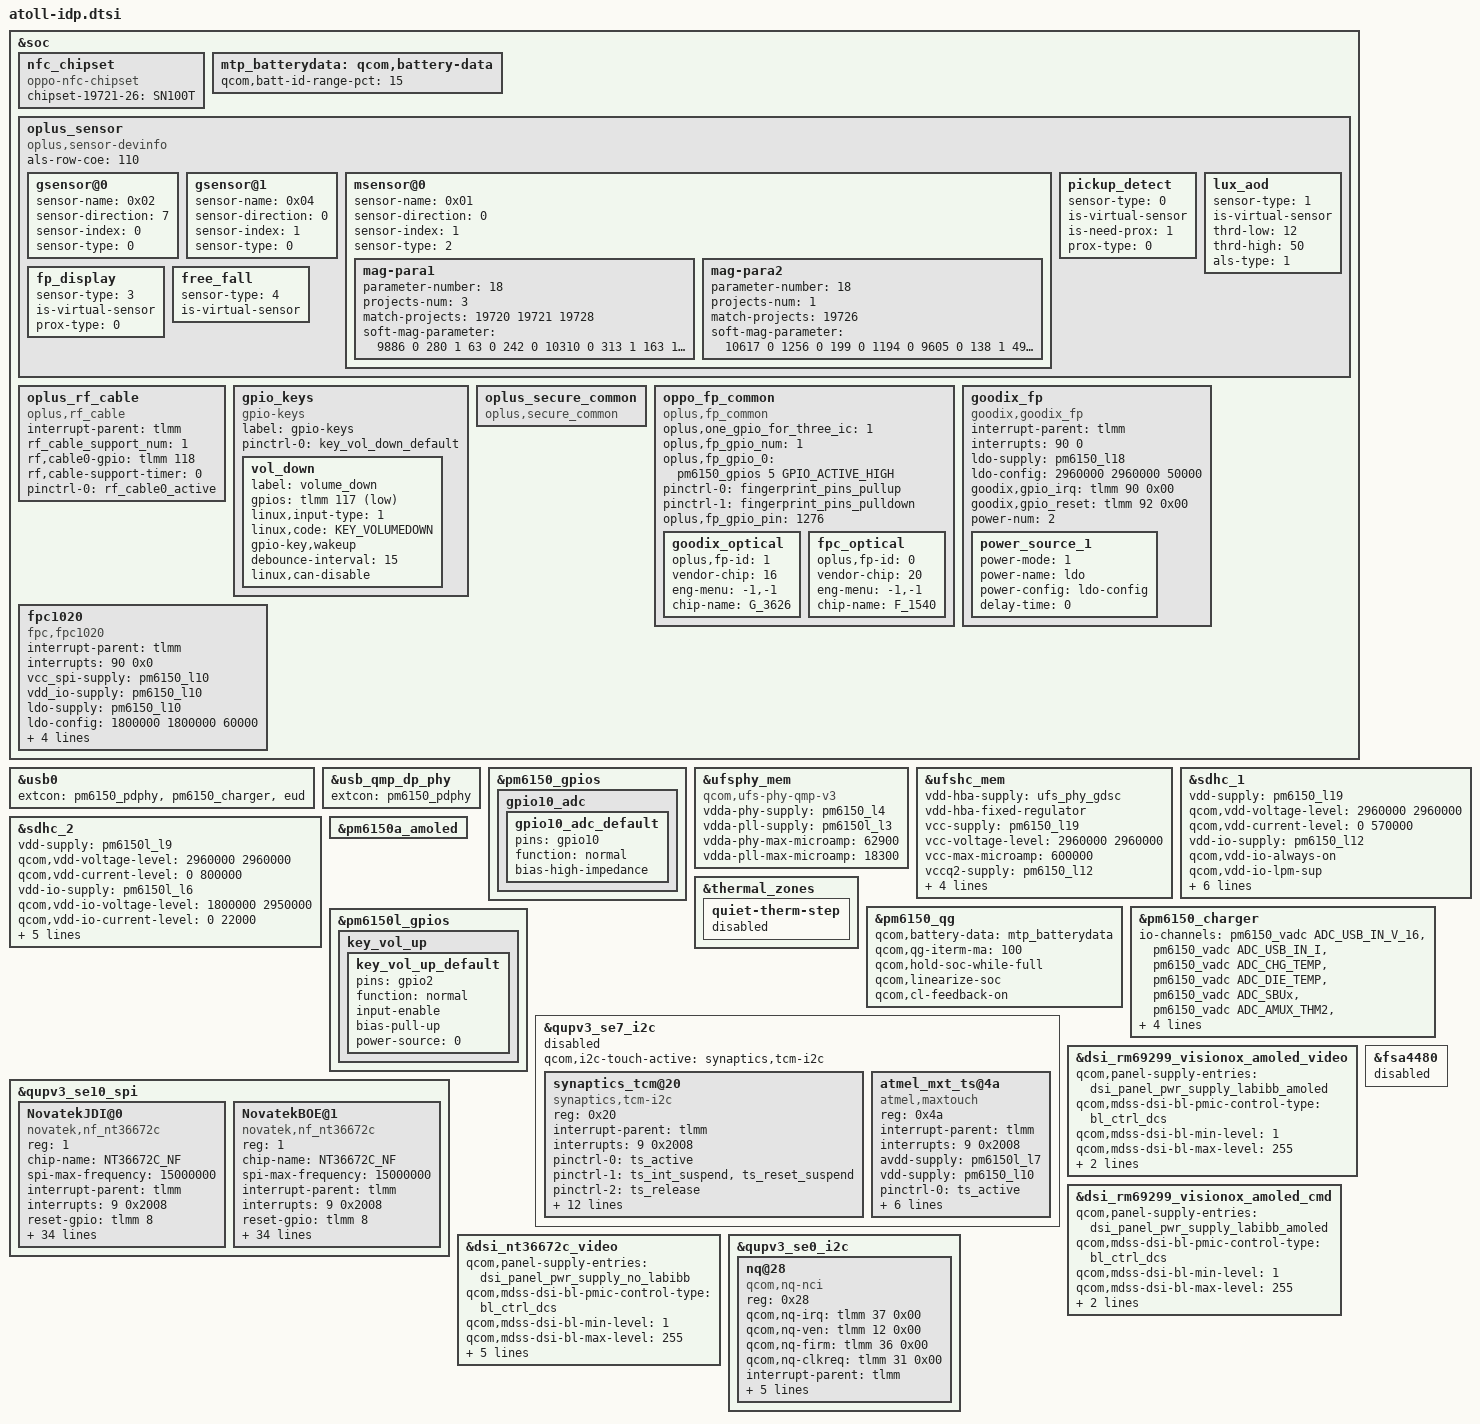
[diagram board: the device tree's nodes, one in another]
/* Copyright (c) 2019-2020, The Linux Foundation. All rights reserved.
 *
 * This program is free software; you can redistribute it and/or modify
 * it under the terms of the GNU General Public License version 2 and
 * only version 2 as published by the Free Software Foundation.
 *
 * This program is distributed in the hope that it will be useful,
 * but WITHOUT ANY WARRANTY; without even the implied warranty of
 * MERCHANTABILITY or FITNESS FOR A PARTICULAR PURPOSE.  See the
 * GNU General Public License for more details.
 */

#include <dt-bindings/gpio/gpio.h>
#include <dt-bindings/pinctrl/qcom,pmic-gpio.h>
#include <dt-bindings/iio/qcom,spmi-vadc.h>
#include <dt-bindings/input/input.h>
#include "atoll-camera-sensor-idp.dtsi"
#include "atoll-sde-display.dtsi"
#include "sdmmagpie-thermal-overlay.dtsi"

&soc {
	//#ifdef VENDOR_EDIT
	nfc_chipset {
		compatible = "oppo-nfc-chipset";
		chipset-19721-26 = "SN100T";
	};
	//#endif /* VENDOR_EDIT */

	mtp_batterydata: qcom,battery-data {
		qcom,batt-id-range-pct = <15>;
		#include "qg-batterydata-alium-3600mah.dtsi"
	};
	//#ifdef VENDOR_EDIT
	/*enum sensor_id { OPPO_ACCEL,OPPO_GYRO,OPPO_MAG,OPPO_LIGHT,OPPO_PROXIMITY,OPPO_SAR,OPPO_CT,OPPO_BAROMETER,SENSORS_NUM};*/
	oplus_sensor {
		compatible = "oplus,sensor-devinfo";
		als-row-coe = <110>;
		/*enum {LSM6DSM = 0x01, BMI160 = 0x02, LSM6DS3 = 0x04};*/
		gsensor@0 {
			sensor-name = <0x02>;//BMI160
			sensor-direction = <7>;
			sensor-index = <0>;//source num
			sensor-type = <0>;//OPPO_ACCEL
		};
		gsensor@1 {
			sensor-name = <0x04>;//LSM6DS3
			sensor-direction = <0>;
			sensor-index = <1>;//source num
			sensor-type = <0>;//OPPO_ACCEL
		};
		/* enum {AKM0991X = 0x01, MMC5603 = 0x02};*/
        msensor@0 {
            sensor-name = <0x01>;//AKM0991X
            sensor-direction = <0>;
            sensor-index = <1>;
            sensor-type = <2>;//OPPO_MAG
            mag-para1 {
                parameter-number= <18>;
                projects-num = <3>;
                match-projects = <19720 19721 19728>;
                soft-mag-parameter = <9886 0 280 1 63 0 242 0 10310 0 313 1 163 1 134 1 10269 0>;//e00 sign e01 sign...
            };
            mag-para2 {
                parameter-number= <18>;
                projects-num = <1>;
                match-projects = <19726>;
                soft-mag-parameter = <10617 0 1256 0 199 0 1194 0 9605 0 138 1 498 0 1171 1 10202 0>;//e00 sign e01 sign...
            };

        };
        /*enum {STK3A5X=0x01,TCS3701=0x02,TCS3408=0x04};*/
        /*lsensor@0 {
            sensor-name = <0x01>;//STK3A5X=0x01
            sensor-index = <0>;
            sensor-type = <3>;//OPPO_LIGHT
            bus-number = <5>;
            irq-number = <93>;
			als-type = <2>;
			is-unit-device = <1>;
			is-als-dri = <1>;
			als-factor = <110>;
			is_als_initialed = <0>;
			als_buffer_length = <10>;
		};
		psensor@0 {
			sensor-name = <0x01>;//STK3A5X
			sensor-index = <0>;
			sensor-type = <4>;//OPPO_PROXIMITY
			bus-number = <5>;
			irq-number = <93>;
			ps-cail-type = <2>;
			ps-type = <1>;
			is_ps_initialzed = <0>;
			low_step = <300>;
			high_step = <400>;
			low_limit = <400>;
			high_limit = <600>;
			dirty_low_step = <100>;
			dirty_high_step = <150>;
			ps_dirty_limit = <1020>;
			ps_ir_limit = <500>;
			ps_adjust_min = <0>;
			ps_adjust_max = <600>;
			sampling_count = <5>;
			step_max = <400>;
			step_min = <100>;
			step_div = <1500>;
			anti_shake_delta = <80>;
			dynamic_cali_max = <1024>;
			raw2offset_radio = <20800>;
			offset_max = <250>;
			offset_range_min = <0xFFFFFF01>;// -255
			offset_range_max = <255>;
			force_cali_limit = <2000>;
			cali_jitter_limit = <20>;
			cal_offset_margin = <80>;
		};*/
		/*virtual sensor
		enum sensor_algo_id {
			OPPO_PICKUP_DETECT,
			OPPO_LUX_AOD,
			OPPO_TP_GESTURE,
			OPPO_FP_DISPLAY,
			OPPO_FREE_FALL,
			OPPO_CAMERA_PROTECT,
			SENSOR_ALGO_NUM
		}*/
		pickup_detect {
			sensor-type = <0>; //OPPO_PICKUP_DETECT
			is-virtual-sensor;
			is-need-prox = <1>;
			prox-type = <0>; // 0 - proximity; 1 - proximity_fake
		};
		lux_aod {
			sensor-type = <1>; //OPPO_LUX_AOD
			is-virtual-sensor;
			thrd-low = <12>;
			thrd-high = <50>;
			als-type = <1>; // 0 - ambient_light; 1 - wise_light
		};
		fp_display {
			sensor-type = <3>; //OPPO_FP_DISPLAY
			is-virtual-sensor;
			prox-type = <0>; // 0 - proximity; 1 - proximity_fake
		};
		free_fall {
			sensor-type = <4>; //OPPO_FREE_FALL
			is-virtual-sensor;
		};
	};
	//#endif /*VENDOR_EDIT*/
	
	//#ifdef VENDOR_EDIT
	oplus_rf_cable {
		compatible = "oplus,rf_cable";
		interrupt-parent = <&tlmm>;
		rf_cable_support_num = <1>;
		rf,cable0-gpio = <&tlmm 118 0>;
		rf,cable-support-timer = <0>;
		pinctrl-names = "rf_cable_active";
		pinctrl-0 = <&rf_cable0_active>;
	};
	//#endif /* VENDOR_EDIT */
};
/*#ifndef ODM_LQ_EDIT*/
/*
&pm6150l_vadc {
	pa_therm1 {
		reg = <ADC_AMUX_THM3_PU2>;
		label = "pa_therm1";
		qcom,ratiometric;
		qcom,hw-settle-time = <200>;
		qcom,pre-scaling = <1 1>;
	};
};

&pm6150l_adc_tm {
	io-channels = <&pm6150l_vadc ADC_AMUX_THM1_PU2>,
			<&pm6150l_vadc ADC_AMUX_THM2_PU2>,
			<&pm6150l_vadc ADC_AMUX_THM3_PU2>,
			<&pm6150l_vadc ADC_GPIO1_PU2>;

	pa_therm1 {
		reg = <ADC_AMUX_THM3_PU2>;
		qcom,ratiometric;
		qcom,hw-settle-time = <200>;
	};
};
*/
/*endif*/
&usb0 {
	extcon = <&pm6150_pdphy>, <&pm6150_charger>, <&eud>;
};

&usb_qmp_dp_phy {
	extcon = <&pm6150_pdphy>;
};

//#ifdef VENDOR_EDIT
&pm6150_gpios{
	gpio10_adc {
		gpio10_adc_default: gpio10_adc_default {
			pins = "gpio10"; /* GPIO 10 */
			function = "normal"; /* normal */
			bias-high-impedance; /* DISABLE GPIO10 for ADC*/
		};
	};
};
//#endif

&ufsphy_mem {
	compatible = "qcom,ufs-phy-qmp-v3";

	vdda-phy-supply = <&pm6150_l4>; /* 0.9v */
	vdda-pll-supply = <&pm6150l_l3>; /* 1.2v */
	vdda-phy-max-microamp = <62900>;
	vdda-pll-max-microamp = <18300>;

	status = "ok";
};

&ufshc_mem {
	vdd-hba-supply = <&ufs_phy_gdsc>;
	vdd-hba-fixed-regulator;
	vcc-supply = <&pm6150_l19>;
	vcc-voltage-level = <2960000 2960000>;
	vcc-max-microamp = <600000>;
	vccq2-supply = <&pm6150_l12>;
	vccq2-voltage-level = <1750000 1950000>;
	vccq2-max-microamp = <600000>;

	qcom,vddp-ref-clk-supply = <&pm6150l_l3>; /* PX10 */
	qcom,vddp-ref-clk-max-microamp = <100>;

	status = "ok";
};

&sdhc_1 {
	vdd-supply = <&pm6150_l19>;
	qcom,vdd-voltage-level = <2960000 2960000>;
	qcom,vdd-current-level = <0 570000>;

	vdd-io-supply = <&pm6150_l12>;
	qcom,vdd-io-always-on;
	qcom,vdd-io-lpm-sup;
	qcom,vdd-io-voltage-level = <1800000 1800000>;
	qcom,vdd-io-current-level = <0 325000>;

	pinctrl-names = "active", "sleep";
	pinctrl-0 = <&sdc1_clk_on &sdc1_cmd_on &sdc1_data_on &sdc1_rclk_on>;
	pinctrl-1 = <&sdc1_clk_off &sdc1_cmd_off &sdc1_data_off &sdc1_rclk_off>;

	status = "ok";
};

&sdhc_2 {
	vdd-supply = <&pm6150l_l9>;
	qcom,vdd-voltage-level = <2960000 2960000>;
	qcom,vdd-current-level = <0 800000>;

	vdd-io-supply = <&pm6150l_l6>;
	qcom,vdd-io-voltage-level = <1800000 2950000>;
	qcom,vdd-io-current-level = <0 22000>;

	pinctrl-names = "active", "sleep";
//#ifndef VENDOR_EDIT
	//pinctrl-0 = <&sdc2_clk_on  &sdc2_cmd_on &sdc2_data_on &sdc2_cd_on>;
//#else
	pinctrl-0 = <&sdc2_clk_on  &sdc2_cmd_on &sdc2_data_on &sdc2_cd_on &sd_detect_default>;
//#endif
	pinctrl-1 = <&sdc2_clk_off &sdc2_cmd_off &sdc2_data_off &sdc2_cd_off>;

//#ifndef VENDOR_EDIT
	//cd-gpios = <&tlmm 69 GPIO_ACTIVE_LOW>;
//#else
    cd-gpios = <&tlmm 69 GPIO_ACTIVE_HIGH>;
//#endif

	status = "ok";
};

&thermal_zones {
/*#ifndef ODM_LQ_EDIT*/
/*
	pa-therm1 {
		polling-delay-passive = <0>;
		polling-delay = <0>;
		thermal-governor = "user_space";
		thermal-sensors = <&pm6150l_adc_tm ADC_AMUX_THM3_PU2>;
		wake-capable-sensor;
		trips {
			active-config0 {
				temperature = <125000>;
				hysteresis = <1000>;
				type = "passive";
			};
		};
	};
*/
/*endif*/
	quiet-therm-step {
		status = "disabled";
	};
};

&pm6150a_amoled {
	status = "ok";
};

&pm6150_qg {
	qcom,battery-data = <&mtp_batterydata>;
	qcom,qg-iterm-ma = <100>;
	qcom,hold-soc-while-full;
	qcom,linearize-soc;
	qcom,cl-feedback-on;
};

&pm6150_charger {
	io-channels = <&pm6150_vadc ADC_USB_IN_V_16>,
		      <&pm6150_vadc ADC_USB_IN_I>,
		      <&pm6150_vadc ADC_CHG_TEMP>,
		      <&pm6150_vadc ADC_DIE_TEMP>,
//#ifdef VENDOR_EDIT
//		      <&pm6150_vadc ADC_AMUX_THM3_PU2>,
//#endif
		      <&pm6150_vadc ADC_SBUx>,
//#ifdef VENDOR_EDIT
		      <&pm6150_vadc ADC_AMUX_THM2>,
		      <&pm6150_vadc ADC_AMUX_THM3>,
//#endif
		      <&pm6150_vadc ADC_VPH_PWR>;
	io-channel-names = "usb_in_voltage",
			   "usb_in_current",
			   "chg_temp",
			   "die_temp",
//#ifdef VENDOR_EDIT
//			   "conn_temp",
//#endif
			   "sbux_res",
//#ifdef VENDOR_EDIT
			   "usb_temp_adc",
     		   "usb_supplementary_temp_adc",
//#endif
			   "vph_voltage";
	qcom,battery-data = <&mtp_batterydata>;
//#ifndef VENDOR_EDIT
//	qcom,auto-recharge-soc = <98>;
//	qcom,step-charging-enable;
//	qcom,sw-jeita-enable;
//	qcom,fcc-stepping-enable;
//	qcom,suspend-input-on-debug-batt;
//	qcom,sec-charger-config = <3>;
//	qcom,thermal-mitigation = <4200000 3500000 3000000
//			2500000 2000000 1500000 1000000 500000>;
//#endif

	dpdm-supply = <&qusb_phy0>;
//#ifndef VENDOR_EDIT
//	qcom,charger-temp-max = <800>;
//	qcom,smb-temp-max = <800>;
//	qcom,fcc-step-delay-ms = <100>;
//	qcom,fcc-step-size-ua = <100000>;
//	qcom,disable-sw-thermal-regulation;
//	qcom,disable-fcc-restriction;
//	qcom,smb-internal-pull-kohm = <0>;
//#endif
};

&pm6150l_gpios {
	key_vol_up {
		key_vol_up_default: key_vol_up_default {
			pins = "gpio2";
			function = "normal";
			input-enable;
			bias-pull-up;
			power-source = <0>;
		};
	};
};

&soc {

	gpio_keys {
		compatible = "gpio-keys";
		label = "gpio-keys";

		pinctrl-names = "default";
		/*#ifdef ODM_LQ_EDIT*/
		pinctrl-0 = <&key_vol_down_default>;
		/*#else*/
		/*
		pinctrl-0 = <&key_vol_up_default>;

		vol_up {
			label = "volume_up";
			gpios = <&pm6150l_gpios 2 GPIO_ACTIVE_LOW>;
			linux,input-type = <1>;
			linux,code = <KEY_VOLUMEUP>;
			linux,can-disable;
			debounce-interval = <15>;
			gpio-key,wakeup;
		};
                */
		/*#endif ODM_LQ_EDIT*/
/*#ifdef ODM_LQ_EDIT*/
		vol_down {
			label = "volume_down";
			gpios = <&tlmm 117 GPIO_ACTIVE_LOW>;
			linux,input-type = <1>;
			linux,code = <KEY_VOLUMEDOWN>;
			gpio-key,wakeup;
			debounce-interval = <15>;
			linux,can-disable;
		};
/*#endif  ODM_LQ_EDIT*/
	};
    // #ifdef OPLUS_FEATURE_SECURITY_COMMON
    oplus_secure_common {
        compatible = "oplus,secure_common";
    };
    //#endif //OPLUS_FEATURE_SECURITY_COMMON

//#ifdef OPLUS_FEATURE_FINGERPRINT
		oppo_fp_common {
			compatible = "oplus,fp_common";
			oplus,one_gpio_for_three_ic = <1>;
			oplus,fp_gpio_num = <1>;
			oplus,fp_gpio_0 = <&pm6150_gpios 5 GPIO_ACTIVE_HIGH>;
			pinctrl-names = "gpio_id0_up", "gpio_id0_down";
			pinctrl-0 = <&fingerprint_pins_pullup>;
			pinctrl-1 = <&fingerprint_pins_pulldown>;
			oplus,fp_gpio_pin = <1276>; // &pm6150_gpios 5, Q = 1275, R = 1276

			goodix_optical {
				oplus,fp-id = <1>; /* pin state unconnected, fp id mapping table. if pin state pullup, id = 2 */
				vendor-chip = <16>; /* please refer to the struct fp_vendor_t in oppo_fp_commmon.n */
				eng-menu = "-1,-1"; /* represents SNR, inclination test item in engineer menu, and 0/1 means off/on */
				chip-name = "G_3626";  /* /proc/fp_id, will be displayed in engineer menu  */
			};
			fpc_optical {
				oplus,fp-id = <0>; /* pin state pulldown, fp id mapping table */
				vendor-chip = <20>; /* please refer to the struct fp_vendor_t in oppo_fp_commmon.n */
				eng-menu = "-1,-1"; /* represents SNR, inclination test item in engineer menu, and 0/1 means off/on */
				chip-name = "F_1540";  /* /proc/fp_id, will be displayed in engineer menu  */
			};
		};

		goodix_fp {
			status = "ok";
			compatible = "goodix,goodix_fp";
			interrupt-parent = <&tlmm>;
			interrupts = <90 0>;
			ldo-supply = <&pm6150_l18>;
			ldo-config = <2960000 2960000 50000>;
			goodix,gpio_irq = <&tlmm 90 0x00>;
			goodix,gpio_reset = <&tlmm 92 0x00>;
			pinctrl-names = "default";
//			pinctrl-0 = <&gpio_goodix_irq_default>;
//			pinctrl-1 = <&goodix_pwr_default>;
			power-num = <2> ;
			power_source_1 {
				power-mode = <1>;   /* 1 = ldo power, refer to oplus_fp_common.h*/
				power-name = "ldo";
				power-config = "ldo-config";
				delay-time = <0>;
			};
		};

		fpc1020 {
			status = "ok";
			compatible = "fpc,fpc1020";
			interrupt-parent = <&tlmm>;
			interrupts = <90 0x0>;
			vcc_spi-supply = <&pm6150_l10>;
			vdd_io-supply  = <&pm6150_l10>;
			ldo-supply = <&pm6150_l10>;
			ldo-config = <1800000 1800000 60000>;
			vdd_ana-supply = <&pm6150_l10>;
			fpc,reset-gpio = <&tlmm 92 0x0>;
			fpc,irq-gpio   = <&tlmm 90 0x0>;
			fpc,enable-on-boot;
			pinctrl-names = "default";
//			pinctrl-0 = <&gpio_fpc_irq_default>;
		};
//#endif /*OPLUS_FEATURE_FINGERPRINT*/
};

&qupv3_se7_i2c {
/*#ifndef ODM_LQ_EDIT*/
//	status = "ok";
/*#else*/
	status = "disabled";
/*#endif*/

	qcom,i2c-touch-active = "synaptics,tcm-i2c";

	synaptics_tcm@20 {
		compatible = "synaptics,tcm-i2c";
		reg = <0x20>;
		interrupt-parent = <&tlmm>;
		interrupts = <9 0x2008>;
		pinctrl-names = "pmx_ts_active","pmx_ts_suspend",
			"pmx_ts_release";
		pinctrl-0 = <&ts_active>;
		pinctrl-1 = <&ts_int_suspend &ts_reset_suspend>;
		pinctrl-2 = <&ts_release>;
		vdd-supply = <&pm6150_l10>;
		avdd-supply = <&pm6150l_l7>;
		synaptics,pwr-reg-name = "avdd";
		synaptics,bus-reg-name = "vdd";
		synaptics,irq-gpio = <&tlmm 9 0x2008>;
		synaptics,irq-on-state = <0>;
		synaptics,reset-gpio = <&tlmm 8 0x00>;
		synaptics,reset-on-state = <0>;
		synaptics,reset-active-ms = <20>;
		synaptics,reset-delay-ms = <200>;
		synaptics,power-delay-ms = <200>;
		synaptics,ubl-i2c-addr = <0x20>;
	};

	atmel_mxt_ts@4a {
		compatible = "atmel,maxtouch";
		reg = <0x4a>;
		interrupt-parent = <&tlmm>;
		interrupts = <9 0x2008>;
		avdd-supply = <&pm6150l_l7>;
		vdd-supply = <&pm6150_l10>;
		pinctrl-names = "pmx_ts_active", "pmx_ts_suspend";
		pinctrl-0 = <&ts_active>;
		pinctrl-1 = <&ts_int_suspend &ts_reset_suspend>;

		reset-gpios = <&tlmm 8 0x00>;
		irq-gpios = <&tlmm 9 0x2008>;

		atmel,xy_switch;
		atmel,panel-coords = <0 0 479 799>;
		atmel,display-coords = <0 0 339 769>;
	};
};

&qupv3_se10_spi {
	status = "ok";
	#address-cells = <1>;
	#size-cells = <0>;
	 NovatekJDI@0 {
		status = "ok";
		compatible = "novatek,nf_nt36672c";
		reg = <1>; //Same as CS ID
		chip-name = "NT36672C_NF";
 
		spi-max-frequency = <15000000>;	//4800000,9600000,15000000,19200000
		interrupt-parent = <&tlmm>;
		interrupts = <9 0x2008>;
		reset-gpio = <&tlmm 8 0x00>;
		irq-gpio = <&tlmm 9 0x2001>;
		cs-gpio = <&tlmm 89 0x01>;
		touchpanel,tx-rx-num = <16 36>;
		touchpanel,max-num-support = <10>;
		touchpanel,panel-coords = <1080 2400>;
		touchpanel,display-coords = <1080 2400>;
		touchpanel,touchmajor-limit = <0 54>;

		vid_len = <0>;
		project_id = <19721>;
		platform_support_project = <19721 19721>;
		platform_support_project_dir = <19721 19721>;
		platform_support_project_commandline = "dsi_nt36672c_jdi_video_display", "dsi_nt36672c_boe_video_display";
		platform_support_project_external_name = "NVT_JDI";

		incell_screen;
		fw_update_in_probe_with_headfile;
		fw_edge_limit_support;
		black_gesture_support;
		charger_pump_support;
		headset_pump_support;
		//spurious_fingerprint_support;
		//lcd_trigger_fp_check;
		esd_handle_support;
		black_gesture_test_support;
		game_switch_support;
		noflash_support;
		lcd_trigger_load_tp_fw_support;
		smart_gesture_support;
		new_set_irq_wake_support;
		pressure_report_support;
		fw_update_app_support;
		cs_gpio_need_pull;
		irq_need_dev_resume_ok;
		touchpanel,button-type = <4>;
	};
	NovatekBOE@1 {
		status = "ok";
		compatible = "novatek,nf_nt36672c";
		reg = <1>; //Same as CS ID
		chip-name = "NT36672C_NF";

		spi-max-frequency = <15000000>;	//4800000,9600000,15000000,19200000
		interrupt-parent = <&tlmm>;
		interrupts = <9 0x2008>;
		reset-gpio = <&tlmm 8 0x00>;
		irq-gpio = <&tlmm 9 0x2001>;
		cs-gpio = <&tlmm 89 0x01>;
		touchpanel,tx-rx-num = <18 36>;
		touchpanel,max-num-support = <10>;
		touchpanel,panel-coords = <1080 2400>;
		touchpanel,display-coords = <1080 2400>;
		touchpanel,touchmajor-limit = <0 54>;

		vid_len = <0>;
		project_id = <19721>;
		platform_support_project = <19721 19721>;
		platform_support_project_dir = <19721 19721>;
		platform_support_project_commandline = "dsi_nt36672c_jdi_video_display", "dsi_nt36672c_boe_video_display";
		platform_support_project_external_name = "NVT_BOE";

		incell_screen;
		fw_update_in_probe_with_headfile;
		fw_edge_limit_support;
		black_gesture_support;
		charger_pump_support;
		headset_pump_support;
		//spurious_fingerprint_support;
		//lcd_trigger_fp_check;
		esd_handle_support;
		black_gesture_test_support;
		game_switch_support;
		noflash_support;
		lcd_trigger_load_tp_fw_support;
		smart_gesture_support;
		new_set_irq_wake_support;
		pressure_report_support;
		fw_update_app_support;
		cs_gpio_need_pull;
		irq_need_dev_resume_ok;
		touchpanel,button-type = <4>;
	};
};

&dsi_rm69299_visionox_amoled_video {
	qcom,panel-supply-entries = <&dsi_panel_pwr_supply_labibb_amoled>;
	qcom,mdss-dsi-bl-pmic-control-type = "bl_ctrl_dcs";
	qcom,mdss-dsi-bl-min-level = <1>;
	qcom,mdss-dsi-bl-max-level = <255>;
	qcom,platform-te-gpio = <&tlmm 10 0>;
	qcom,platform-reset-gpio = <&pm6150l_gpios 3 0>;
};

&dsi_rm69299_visionox_amoled_cmd {
	qcom,panel-supply-entries = <&dsi_panel_pwr_supply_labibb_amoled>;
	qcom,mdss-dsi-bl-pmic-control-type = "bl_ctrl_dcs";
	qcom,mdss-dsi-bl-min-level = <1>;
	qcom,mdss-dsi-bl-max-level = <255>;
	qcom,platform-te-gpio = <&tlmm 10 0>;
	qcom,platform-reset-gpio = <&pm6150l_gpios 3 0>;
};

&dsi_nt36672c_video {
	qcom,panel-supply-entries = <&dsi_panel_pwr_supply_no_labibb>;
	qcom,mdss-dsi-bl-pmic-control-type = "bl_ctrl_dcs";
	qcom,mdss-dsi-bl-min-level = <1>;
	qcom,mdss-dsi-bl-max-level = <255>;
	qcom,platform-te-gpio = <&tlmm 10 0>;
	qcom,platform-reset-gpio = <&pm6150l_gpios 3 0>;
	qcom,platform-bklight-en-gpio = <&pm6150l_gpios 10 0>;
	qcom,platform-en-gpio = <&pm6150l_gpios 4 0>;
};

&qupv3_se0_i2c {
	status = "ok";
       //#ifndef VENDOR_EDIT
       //qcom,clk-freq-out = <1000000>;
       //#endif /* VENDOR_EDIT */
	#address-cells = <1>;
	#size-cells = <0>;
	nq@28 {
		compatible = "qcom,nq-nci";
		reg = <0x28>;
		qcom,nq-irq = <&tlmm 37 0x00>;
		qcom,nq-ven = <&tlmm 12 0x00>;
		qcom,nq-firm = <&tlmm 36 0x00>;
		qcom,nq-clkreq = <&tlmm 31 0x00>;
		interrupt-parent = <&tlmm>;
		interrupts = <37 0>;
		interrupt-names = "nfc_irq";
		pinctrl-names = "nfc_active", "nfc_suspend";
		pinctrl-0 = <&nfc_int_active &nfc_enable_active
				&nfc_clk_req_active>;
		pinctrl-1 = <&nfc_int_suspend &nfc_enable_suspend
				&nfc_clk_req_suspend>;
	};
};

/*	
&sde_dp{
	qcom,dp-aux-switch = <&fsa4480>;
};*/

&fsa4480{
	status="disabled";
};

//#ifdef VENDOR_EDIT
#include "oppo-charge.dtsi"
//endif
